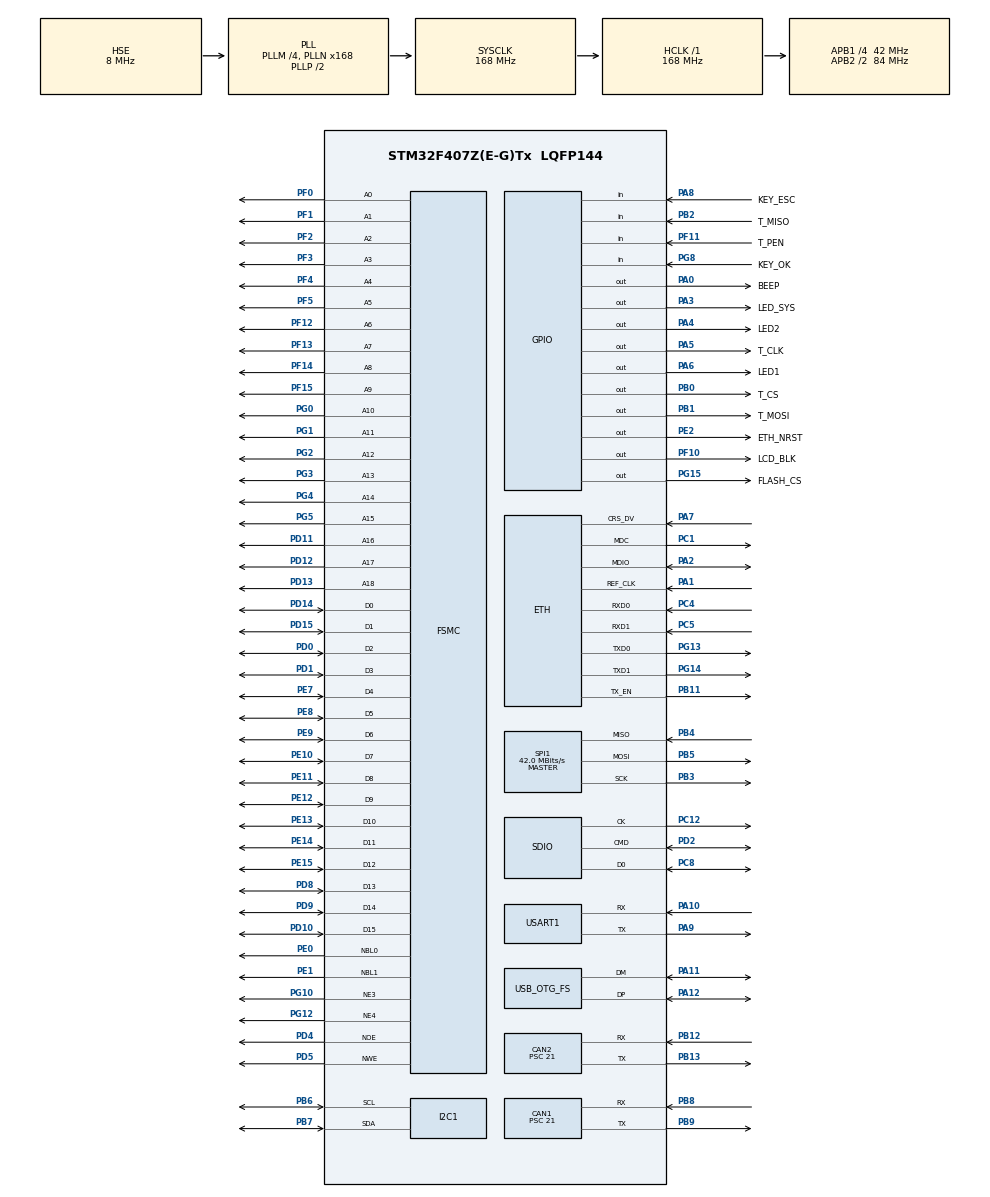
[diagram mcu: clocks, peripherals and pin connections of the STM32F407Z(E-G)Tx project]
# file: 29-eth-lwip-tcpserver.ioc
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CAN1.BS1=CAN_BS1_2TQ
CAN1.CalculateBaudRate=500000
CAN1.CalculateTimeBit=2000
CAN1.CalculateTimeQuantum=500.0
CAN1.Prescaler=21
CAN2.BS1=CAN_BS1_2TQ
CAN2.CalculateBaudRate=500000
CAN2.CalculateTimeBit=2000
CAN2.CalculateTimeQuantum=500.0
CAN2.Prescaler=21
Dma.Request0=USART1_RX
Dma.Request1=SDIO_RX
Dma.Request2=SDIO_TX
Dma.SDIO_RX.1.Direction=DMA_PERIPH_TO_MEMORY
Dma.SDIO_RX.1.FIFOMode=DMA_FIFOMODE_ENABLE
Dma.SDIO_RX.1.FIFOThreshold=DMA_FIFO_THRESHOLD_FULL
Dma.SDIO_RX.1.Instance=DMA2_Stream3
Dma.SDIO_RX.1.MemBurst=DMA_MBURST_INC4
Dma.SDIO_RX.1.MemDataAlignment=DMA_MDATAALIGN_WORD
Dma.SDIO_RX.1.MemInc=DMA_MINC_ENABLE
Dma.SDIO_RX.1.Mode=DMA_PFCTRL
Dma.SDIO_RX.1.PeriphBurst=DMA_PBURST_INC4
Dma.SDIO_RX.1.PeriphDataAlignment=DMA_PDATAALIGN_WORD
Dma.SDIO_RX.1.PeriphInc=DMA_PINC_DISABLE
Dma.SDIO_RX.1.Priority=DMA_PRIORITY_LOW
Dma.SDIO_TX.2.Direction=DMA_MEMORY_TO_PERIPH
Dma.SDIO_TX.2.FIFOMode=DMA_FIFOMODE_ENABLE
Dma.SDIO_TX.2.FIFOThreshold=DMA_FIFO_THRESHOLD_FULL
Dma.SDIO_TX.2.Instance=DMA2_Stream6
Dma.SDIO_TX.2.MemBurst=DMA_MBURST_INC4
Dma.SDIO_TX.2.MemDataAlignment=DMA_MDATAALIGN_WORD
Dma.SDIO_TX.2.MemInc=DMA_MINC_ENABLE
Dma.SDIO_TX.2.Mode=DMA_PFCTRL
Dma.SDIO_TX.2.PeriphBurst=DMA_PBURST_INC4
Dma.SDIO_TX.2.PeriphDataAlignment=DMA_PDATAALIGN_WORD
Dma.SDIO_TX.2.PeriphInc=DMA_PINC_DISABLE
Dma.SDIO_TX.2.Priority=DMA_PRIORITY_LOW
Dma.USART1_RX.0.Direction=DMA_PERIPH_TO_MEMORY
Dma.USART1_RX.0.FIFOMode=DMA_FIFOMODE_DISABLE
Dma.USART1_RX.0.Instance=DMA2_Stream2
Dma.USART1_RX.0.MemDataAlignment=DMA_MDATAALIGN_BYTE
Dma.USART1_RX.0.MemInc=DMA_MINC_ENABLE
Dma.USART1_RX.0.Mode=DMA_CIRCULAR
Dma.USART1_RX.0.PeriphDataAlignment=DMA_PDATAALIGN_BYTE
Dma.USART1_RX.0.PeriphInc=DMA_PINC_DISABLE
Dma.USART1_RX.0.Priority=DMA_PRIORITY_LOW
ETH.MediaInterface=HAL_ETH_RMII_MODE
FSMC.AddressSetupTime3=0
FSMC.AddressSetupTime4=0
FSMC.BusTurnAroundDuration3=0
FSMC.DataSetupTime3=10
FSMC.DataSetupTime4=4
FSMC.ExtendedMode4=FSMC_EXTENDED_MODE_ENABLE
FSMC.WriteOperation3=FSMC_WRITE_OPERATION_ENABLE
LWIP.BSP.number=1
LWIP.GATEWAY_ADDRESS=192.168.032.001
LWIP.IP_ADDRESS=192.168.032.001
LWIP.LWIP_DHCP=0
LWIP.NETMASK_ADDRESS=255.255.255.000
LWIP.Version=v2.1.2_Cube
LWIP0.BSP.STBoard=false
LWIP0.BSP.api=BSP_COMPONENT_DRIVER
LWIP0.BSP.component=LAN8742
LWIP0.BSP.instance=LAN8742
LWIP0.BSP.name=Driver_PHY
LWIP0.BSP.semaphore=S_LAN8742
LWIP0.BSP.solution=LAN8742
Mcu.Family=STM32F4
Mcu.Name=STM32F407Z(E-G)Tx
Mcu.Package=LQFP144
NVIC.CAN1_RX0_IRQn=true\:0\:0\:false\:false\:true\:true\:true\:true
NVIC.CAN1_TX_IRQn=true\:0\:0\:false\:false\:true\:true\:true\:true
NVIC.DMA2_Stream2_IRQn=true\:0\:0\:false\:false\:true\:false\:true\:true
NVIC.DMA2_Stream3_IRQn=true\:0\:0\:false\:false\:true\:false\:true\:true
NVIC.DMA2_Stream6_IRQn=true\:0\:0\:false\:false\:true\:false\:true\:true
NVIC.OTG_FS_IRQn=true\:0\:0\:false\:false\:true\:false\:true\:true
NVIC.PriorityGroup=NVIC_PRIORITYGROUP_4
NVIC.SDIO_IRQn=true\:0\:0\:false\:false\:true\:true\:true\:true
NVIC.TIM2_IRQn=true\:0\:0\:false\:false\:true\:true\:true\:true
NVIC.USART1_IRQn=true\:0\:0\:false\:false\:true\:true\:true\:true
PA0-WKUP.GPIO_Label=BEEP
PA0-WKUP.Signal=GPIO_Output
PA1.Mode=RMII
PA1.Signal=ETH_REF_CLK
PA10.GPIO_PuPd=GPIO_PULLUP
PA10.Mode=Asynchronous
PA10.Signal=USART1_RX
PA11.Mode=Device_Only
PA11.Signal=USB_OTG_FS_DM
PA12.Mode=Device_Only
PA12.Signal=USB_OTG_FS_DP
PA13.Mode=Serial_Wire
PA13.Signal=SYS_JTMS-SWDIO
PA14.Mode=Serial_Wire
PA14.Signal=SYS_JTCK-SWCLK
PA2.Mode=RMII
PA2.Signal=ETH_MDIO
PA3.GPIO_Label=LED_SYS
PA3.PinState=GPIO_PIN_SET
PA3.Signal=GPIO_Output
PA4.GPIO_Label=LED2
PA4.PinState=GPIO_PIN_SET
PA4.Signal=GPIO_Output
PA5.GPIO_Label=T_CLK
PA5.GPIO_Speed=GPIO_SPEED_FREQ_VERY_HIGH
PA5.PinState=GPIO_PIN_SET
PA5.Signal=GPIO_Output
PA6.GPIO_Label=LED1
PA6.PinState=GPIO_PIN_SET
PA6.Signal=GPIO_Output
PA7.Mode=RMII
PA7.Signal=ETH_CRS_DV
PA8.GPIO_Label=KEY_ESC
PA8.GPIO_PuPd=GPIO_PULLUP
PA8.Signal=GPIO_Input
PA9.GPIO_PuPd=GPIO_PULLUP
PA9.Mode=Asynchronous
PA9.Signal=USART1_TX
PB0.GPIO_Label=T_CS
PB0.GPIO_Speed=GPIO_SPEED_FREQ_VERY_HIGH
PB0.PinState=GPIO_PIN_SET
PB0.Signal=GPIO_Output
PB1.GPIO_Label=T_MOSI
PB1.GPIO_Speed=GPIO_SPEED_FREQ_VERY_HIGH
PB1.PinState=GPIO_PIN_SET
PB1.Signal=GPIO_Output
PB11.Mode=RMII
PB11.Signal=ETH_TX_EN
PB12.Mode=CAN_Activate
PB12.Signal=CAN2_RX
PB13.Mode=CAN_Activate
PB13.Signal=CAN2_TX
PB2.GPIO_Label=T_MISO
PB2.GPIO_PuPd=GPIO_PULLUP
PB2.Signal=GPIO_Input
PB3.Mode=Full_Duplex_Master
PB3.Signal=SPI1_SCK
PB4.Mode=Full_Duplex_Master
PB4.Signal=SPI1_MISO
PB5.Mode=Full_Duplex_Master
PB5.Signal=SPI1_MOSI
PB6.Mode=I2C
PB6.Signal=I2C1_SCL
PB7.Mode=I2C
PB7.Signal=I2C1_SDA
PB8.Mode=CAN_Activate
PB8.Signal=CAN1_RX
PB9.Mode=CAN_Activate
PB9.Signal=CAN1_TX
PC1.Mode=RMII
PC1.Signal=ETH_MDC
PC12.Mode=SD_1_bit
PC12.Signal=SDIO_CK
PC14-OSC32_IN.Mode=LSE-External-Oscillator
PC14-OSC32_IN.Signal=RCC_OSC32_IN
PC15-OSC32_OUT.Mode=LSE-External-Oscillator
PC15-OSC32_OUT.Signal=RCC_OSC32_OUT
PC4.Mode=RMII
PC4.Signal=ETH_RXD0
PC5.Mode=RMII
PC5.Signal=ETH_RXD1
PC8.Mode=SD_1_bit
PC8.Signal=SDIO_D0
PD0.Signal=FSMC_D2_DA2
PD1.Signal=FSMC_D3_DA3
PD10.Signal=FSMC_D15_DA15
PD11.Signal=FSMC_A16_CLE
PD12.Signal=FSMC_A17_ALE
PD13.Signal=FSMC_A18
PD14.Signal=FSMC_D0_DA0
PD15.Signal=FSMC_D1_DA1
PD2.Mode=SD_1_bit
PD2.Signal=SDIO_CMD
PD4.Signal=FSMC_NOE
PD5.Signal=FSMC_NWE
PD8.Signal=FSMC_D13_DA13
PD9.Signal=FSMC_D14_DA14
PE0.Signal=FSMC_NBL0
PE1.Signal=FSMC_NBL1
PE10.Signal=FSMC_D7_DA7
PE11.Signal=FSMC_D8_DA8
PE12.Signal=FSMC_D9_DA9
PE13.Signal=FSMC_D10_DA10
PE14.Signal=FSMC_D11_DA11
PE15.Signal=FSMC_D12_DA12
PE2.GPIO_Label=ETH_NRST
PE2.GPIO_Speed=GPIO_SPEED_FREQ_VERY_HIGH
PE2.PinState=GPIO_PIN_SET
PE2.Signal=GPIO_Output
PE7.Signal=FSMC_D4_DA4
PE8.Signal=FSMC_D5_DA5
PE9.Signal=FSMC_D6_DA6
PF0.Signal=FSMC_A0
PF1.Signal=FSMC_A1
PF10.GPIO_Label=LCD_BLK
PF10.GPIO_Speed=GPIO_SPEED_FREQ_VERY_HIGH
PF10.PinState=GPIO_PIN_SET
PF10.Signal=GPIO_Output
PF11.GPIO_Label=T_PEN
PF11.GPIO_PuPd=GPIO_PULLUP
PF11.Signal=GPIO_Input
PF12.Signal=FSMC_A6
PF13.Signal=FSMC_A7
PF14.Signal=FSMC_A8
PF15.Signal=FSMC_A9
PF2.Signal=FSMC_A2
PF3.Signal=FSMC_A3
PF4.Signal=FSMC_A4
PF5.Signal=FSMC_A5
PG0.Signal=FSMC_A10
PG1.Signal=FSMC_A11
PG10.Mode=NorPsramChipSelect3_3
PG10.Signal=FSMC_NE3
PG12.Mode=NorPsramChipSelect4_4
PG12.Signal=FSMC_NE4
PG13.Mode=RMII
PG13.Signal=ETH_TXD0
PG14.Mode=RMII
PG14.Signal=ETH_TXD1
PG15.GPIO_Label=FLASH_CS
PG15.GPIO_Speed=GPIO_SPEED_FREQ_VERY_HIGH
PG15.PinState=GPIO_PIN_SET
PG15.Signal=GPIO_Output
PG2.Signal=FSMC_A12
PG3.Signal=FSMC_A13
PG4.Signal=FSMC_A14
PG5.Signal=FSMC_A15
PG8.GPIO_Label=KEY_OK
PG8.GPIO_PuPd=GPIO_PULLUP
PG8.Signal=GPIO_Input
PH0-OSC_IN.Mode=HSE-External-Oscillator
PH0-OSC_IN.Signal=RCC_OSC_IN
PH1-OSC_OUT.Mode=HSE-External-Oscillator
PH1-OSC_OUT.Signal=RCC_OSC_OUT
ProjectManager.HeapSize=0x200
ProjectManager.StackSize=0x2000
ProjectManager.TargetToolchain=MDK-ARM V5.32
RCC.48MHZClocksFreq_Value=48000000
RCC.AHBFreq_Value=168000000
RCC.APB1CLKDivider=RCC_HCLK_DIV4
RCC.APB1Freq_Value=42000000
RCC.APB1TimFreq_Value=84000000
RCC.APB2CLKDivider=RCC_HCLK_DIV2
RCC.APB2Freq_Value=84000000
RCC.APB2TimFreq_Value=168000000
RCC.CortexFreq_Value=168000000
RCC.HCLKFreq_Value=168000000
RCC.HSE_VALUE=8000000
RCC.HSI_VALUE=16000000
RCC.PLLM=4
RCC.PLLN=168
RCC.PLLQ=7
RCC.RCC_RTC_Clock_Source=RCC_RTCCLKSOURCE_LSE
RCC.RCC_RTC_Clock_SourceVirtual=RCC_RTCCLKSOURCE_LSE
RCC.SYSCLKFreq_VALUE=168000000
RCC.SYSCLKSource=RCC_SYSCLKSOURCE_PLLCLK
RCC.VCOOutputFreq_Value=336000000
RTC.Date=26
RTC.Hours=9
RTC.Minutes=35
RTC.Month=RTC_MONTH_SEPTEMBER
RTC.WeekDay=RTC_WEEKDAY_SATURDAY
SDIO.ClockDiv=4
SH.FSMC_A0.0=FSMC_A0,19b-a3
SH.FSMC_A1.0=FSMC_A1,19b-a3
SH.FSMC_A10.0=FSMC_A10,19b-a3
SH.FSMC_A11.0=FSMC_A11,19b-a3
SH.FSMC_A12.0=FSMC_A12,19b-a3
SH.FSMC_A12.1=FSMC_A12,A12_4
SH.FSMC_A13.0=FSMC_A13,19b-a3
SH.FSMC_A14.0=FSMC_A14,19b-a3
SH.FSMC_A15.0=FSMC_A15,19b-a3
SH.FSMC_A16_CLE.0=FSMC_A16,19b-a3
SH.FSMC_A17_ALE.0=FSMC_A17,19b-a3
SH.FSMC_A18.0=FSMC_A18,19b-a3
SH.FSMC_A2.0=FSMC_A2,19b-a3
SH.FSMC_A3.0=FSMC_A3,19b-a3
SH.FSMC_A4.0=FSMC_A4,19b-a3
SH.FSMC_A5.0=FSMC_A5,19b-a3
SH.FSMC_A6.0=FSMC_A6,19b-a3
SH.FSMC_A7.0=FSMC_A7,19b-a3
SH.FSMC_A8.0=FSMC_A8,19b-a3
SH.FSMC_A9.0=FSMC_A9,19b-a3
SH.FSMC_D0_DA0.0=FSMC_D0,16b-d3
SH.FSMC_D0_DA0.1=FSMC_D0,16b-d4
SH.FSMC_D10_DA10.0=FSMC_D10,16b-d3
SH.FSMC_D10_DA10.1=FSMC_D10,16b-d4
SH.FSMC_D11_DA11.0=FSMC_D11,16b-d3
SH.FSMC_D11_DA11.1=FSMC_D11,16b-d4
SH.FSMC_D12_DA12.0=FSMC_D12,16b-d3
SH.FSMC_D12_DA12.1=FSMC_D12,16b-d4
SH.FSMC_D13_DA13.0=FSMC_D13,16b-d3
SH.FSMC_D13_DA13.1=FSMC_D13,16b-d4
SH.FSMC_D14_DA14.0=FSMC_D14,16b-d3
SH.FSMC_D14_DA14.1=FSMC_D14,16b-d4
SH.FSMC_D15_DA15.0=FSMC_D15,16b-d3
SH.FSMC_D15_DA15.1=FSMC_D15,16b-d4
SH.FSMC_D1_DA1.0=FSMC_D1,16b-d3
SH.FSMC_D1_DA1.1=FSMC_D1,16b-d4
SH.FSMC_D2_DA2.0=FSMC_D2,16b-d3
SH.FSMC_D2_DA2.1=FSMC_D2,16b-d4
SH.FSMC_D3_DA3.0=FSMC_D3,16b-d3
SH.FSMC_D3_DA3.1=FSMC_D3,16b-d4
SH.FSMC_D4_DA4.0=FSMC_D4,16b-d3
SH.FSMC_D4_DA4.1=FSMC_D4,16b-d4
SH.FSMC_D5_DA5.0=FSMC_D5,16b-d3
SH.FSMC_D5_DA5.1=FSMC_D5,16b-d4
SH.FSMC_D6_DA6.0=FSMC_D6,16b-d3
SH.FSMC_D6_DA6.1=FSMC_D6,16b-d4
SH.FSMC_D7_DA7.0=FSMC_D7,16b-d3
SH.FSMC_D7_DA7.1=FSMC_D7,16b-d4
SH.FSMC_D8_DA8.0=FSMC_D8,16b-d3
SH.FSMC_D8_DA8.1=FSMC_D8,16b-d4
SH.FSMC_D9_DA9.0=FSMC_D9,16b-d3
SH.FSMC_D9_DA9.1=FSMC_D9,16b-d4
SH.FSMC_NBL0.0=FSMC_NBL0,2ByteEnable3
SH.FSMC_NBL1.0=FSMC_NBL1,2ByteEnable3
SH.FSMC_NOE.0=FSMC_NOE,Sram3
SH.FSMC_NOE.1=FSMC_NOE,Lcd4
SH.FSMC_NWE.0=FSMC_NWE,Sram3
SH.FSMC_NWE.1=FSMC_NWE,Lcd4
SPI1.CalculateBaudRate=42.0 MBits/s
SPI1.Direction=SPI_DIRECTION_2LINES
SPI1.Mode=SPI_MODE_MASTER
SPI1.VirtualType=VM_MASTER
TIM2.AutoReloadPreload=TIM_AUTORELOAD_PRELOAD_ENABLE
TIM2.Period=1000
TIM2.Prescaler=83
USART1.VirtualMode=VM_ASYNC
USB_DEVICE.CLASS_NAME_FS=HID
USB_DEVICE.VirtualMode-HID_FS=Hid
USB_DEVICE.VirtualModeFS=Hid_FS
USB_OTG_FS.VirtualMode=Device_Only
VP_LWIP_VS_Enabled.Mode=Enabled
VP_RTC_VS_RTC_Activate.Mode=RTC_Enabled
VP_RTC_VS_RTC_Calendar.Mode=RTC_Calendar
VP_TIM2_VS_ClockSourceINT.Mode=Internal
VP_USB_DEVICE_VS_USB_DEVICE_HID_FS.Mode=HID_FS
board=custom

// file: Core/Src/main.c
/* USER CODE BEGIN Header */
/**
  ******************************************************************************
  * @file           : main.c
  * @brief          : Main program body
  ******************************************************************************
  * @attention
  *
  * Copyright (c) 2026 STMicroelectronics.
  * All rights reserved.
  *
  * This software is licensed under terms that can be found in the LICENSE file
  * in the root directory of this software component.
  * If no LICENSE file comes with this software, it is provided AS-IS.
  *
  ******************************************************************************
  */
/* USER CODE END Header */
#include "main.h"
#include "can.h"
#include "dma.h"
#include "i2c.h"
#include "lwip.h"
#include "rtc.h"
#include "sdio.h"
#include "spi.h"
#include "tim.h"
#include "usart.h"
#include "usb_device.h"
#include "gpio.h"
#include "fsmc.h"

/* USER CODE BEGIN Includes */
#include <stdio.h>

#include "w25qx.h"
#include "tftlcd.h"
#include "xpt2046.h"
#include "tcpserver.h"
/* USER CODE END Includes */

/* USER CODE BEGIN PTD */
extern struct netif gnetif;
struct dhcp *dhcp;
/* USER CODE END PTD */

void SystemClock_Config(void);
/* USER CODE BEGIN PFP */
//extern ApplicationTypeDef Appli_state;
/* USER CODE END PFP */

int main(void)
{

  /* MCU Configuration--------------------------------------------------------*/

  /* Reset of all peripherals, Initializes the Flash interface and the Systick. */
  HAL_Init();

  /* Configure the system clock */
  SystemClock_Config();

  /* Initialize all configured peripherals */
  MX_GPIO_Init();
  MX_DMA_Init();
  MX_USART1_UART_Init();
  MX_RTC_Init();
  MX_I2C1_Init();
  MX_SPI1_Init();
  MX_CAN1_Init();
  MX_CAN2_Init();
  MX_FSMC_Init();
  MX_SDIO_SD_Init();
  MX_USB_DEVICE_Init();
  MX_TIM2_Init();
  MX_LWIP_Init();
  /* USER CODE BEGIN 2 */

	printf("uart1 init");

	__HAL_UART_ENABLE_IT(&huart1, UART_IT_IDLE);//使能串UART1 IDLE(空闲)中断
	HAL_UART_Receive_DMA(&huart1, RX1_Buf, DMA_BUF_SIZE);//设置DMA传输， 将uart1的数据搬运到RX1_Buf中

//	CAN_Init();
//	CAN1_Send_Test();
//	HAL_Delay(5000);
//	CAN2_Send_Test();

//	if(ExtSRAM_Test() == 0)
//	{
//		printf("ExtSRAM Test successs\n");
//	}
//	else
//	{
//		printf("ExtSRAM Test fail\n");
//	}

//	LCD_Init();
//	XPT2046_Init();
//	LCD_Clear(WHITE);
//	POINT_COLOR=RED;//设置字体为蓝色
//	LCD_ShowString(10,10,200,24,24,(uint8_t *)"STM32F407ZG!");
//	LCD_ShowString(10,40,200,24,24,(uint8_t *)"TOUCH TEST");
//	Clear_Screen();
//	R_Touch_test();

//	while(1)
//	{
//		MX_USB_HOST_Process();
//		if(Appli_state == APPLICATION_READY) break;
//	}

//	FatFs_Test();

	HAL_TIM_Base_Start_IT(&htim2);

	tcp_server_start(8000);
	printf("Static IP address: %s\n", ip4addr_ntoa(&gnetif.ip_addr));
	printf("Subnet mask: %s\n", ip4addr_ntoa(&gnetif.netmask));
	printf("Default gateway: %s\n", ip4addr_ntoa(&gnetif.gw));

  /* USER CODE END 2 */

  /* Infinite loop */
  while (1)
  {
	MX_LWIP_Process();

	transfer_data();
  }
}

void SystemClock_Config(void)
{
  RCC_OscInitTypeDef RCC_OscInitStruct = {0};
  RCC_ClkInitTypeDef RCC_ClkInitStruct = {0};

  /** Configure the main internal regulator output voltage
  */
  __HAL_RCC_PWR_CLK_ENABLE();
  __HAL_PWR_VOLTAGESCALING_CONFIG(PWR_REGULATOR_VOLTAGE_SCALE1);

  /** Initializes the RCC Oscillators according to the specified parameters
  * in the RCC_OscInitTypeDef structure.
  */
  RCC_OscInitStruct.OscillatorType = RCC_OSCILLATORTYPE_HSE|RCC_OSCILLATORTYPE_LSE;
  RCC_OscInitStruct.HSEState = RCC_HSE_ON;
  RCC_OscInitStruct.LSEState = RCC_LSE_ON;
  RCC_OscInitStruct.PLL.PLLState = RCC_PLL_ON;
  RCC_OscInitStruct.PLL.PLLSource = RCC_PLLSOURCE_HSE;
  RCC_OscInitStruct.PLL.PLLM = 4;
  RCC_OscInitStruct.PLL.PLLN = 168;
  RCC_OscInitStruct.PLL.PLLP = RCC_PLLP_DIV2;
  RCC_OscInitStruct.PLL.PLLQ = 7;
  if (HAL_RCC_OscConfig(&RCC_OscInitStruct) != HAL_OK)
  {
    Error_Handler();
  }

  /** Initializes the CPU, AHB and APB buses clocks
  */
  RCC_ClkInitStruct.ClockType = RCC_CLOCKTYPE_HCLK|RCC_CLOCKTYPE_SYSCLK
                              |RCC_CLOCKTYPE_PCLK1|RCC_CLOCKTYPE_PCLK2;
  RCC_ClkInitStruct.SYSCLKSource = RCC_SYSCLKSOURCE_PLLCLK;
  RCC_ClkInitStruct.AHBCLKDivider = RCC_SYSCLK_DIV1;
  RCC_ClkInitStruct.APB1CLKDivider = RCC_HCLK_DIV4;
  RCC_ClkInitStruct.APB2CLKDivider = RCC_HCLK_DIV2;

  if (HAL_RCC_ClockConfig(&RCC_ClkInitStruct, FLASH_LATENCY_5) != HAL_OK)
  {
    Error_Handler();
  }
}

void Error_Handler(void)
{
  __disable_irq();
  while (1)
  {
  }
}
